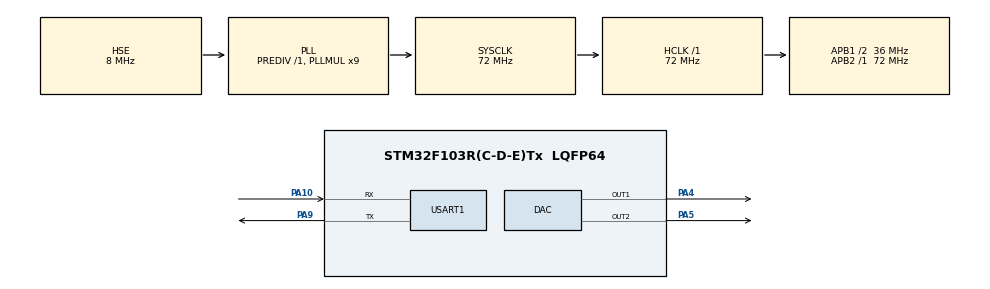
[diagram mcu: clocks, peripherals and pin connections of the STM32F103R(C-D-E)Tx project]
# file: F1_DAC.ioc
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DAC.DAC_Trigger=DAC_TRIGGER_T2_TRGO
DAC.DAC_Trigger2=DAC_TRIGGER_T2_TRGO
Dma.DAC_CH1.0.Direction=DMA_MEMORY_TO_PERIPH
Dma.DAC_CH1.0.Instance=DMA2_Channel3
Dma.DAC_CH1.0.MemDataAlignment=DMA_MDATAALIGN_HALFWORD
Dma.DAC_CH1.0.MemInc=DMA_MINC_ENABLE
Dma.DAC_CH1.0.Mode=DMA_CIRCULAR
Dma.DAC_CH1.0.PeriphDataAlignment=DMA_PDATAALIGN_HALFWORD
Dma.DAC_CH1.0.PeriphInc=DMA_PINC_DISABLE
Dma.DAC_CH1.0.Priority=DMA_PRIORITY_LOW
Dma.DAC_CH2.1.Direction=DMA_MEMORY_TO_PERIPH
Dma.DAC_CH2.1.Instance=DMA2_Channel4
Dma.DAC_CH2.1.MemDataAlignment=DMA_MDATAALIGN_HALFWORD
Dma.DAC_CH2.1.MemInc=DMA_MINC_ENABLE
Dma.DAC_CH2.1.Mode=DMA_CIRCULAR
Dma.DAC_CH2.1.PeriphDataAlignment=DMA_PDATAALIGN_HALFWORD
Dma.DAC_CH2.1.PeriphInc=DMA_PINC_DISABLE
Dma.DAC_CH2.1.Priority=DMA_PRIORITY_LOW
Dma.Request0=DAC_CH1
Dma.Request1=DAC_CH2
Mcu.Family=STM32F1
Mcu.Name=STM32F103R(C-D-E)Tx
Mcu.Package=LQFP64
NVIC.DMA2_Channel3_IRQn=true\:0\:0\:false\:false\:true\:false\:true
NVIC.DMA2_Channel4_5_IRQn=true\:0\:0\:false\:false\:true\:false\:true
NVIC.PriorityGroup=NVIC_PRIORITYGROUP_4
NVIC.TIM3_IRQn=true\:0\:0\:false\:false\:true\:false\:true
NVIC.TimeBase=TIM3_IRQn
NVIC.TimeBaseIP=TIM3
PA10.Mode=Asynchronous
PA10.Signal=USART1_RX
PA13.Mode=Serial_Wire
PA13.Signal=SYS_JTMS-SWDIO
PA14.Mode=Serial_Wire
PA14.Signal=SYS_JTCK-SWCLK
PA4.Signal=COMP_DAC1_group
PA5.Signal=COMP_DAC2_group
PA9.Mode=Asynchronous
PA9.Signal=USART1_TX
PC14-OSC32_IN.Mode=LSE-External-Oscillator
PC14-OSC32_IN.Signal=RCC_OSC32_IN
PC15-OSC32_OUT.Mode=LSE-External-Oscillator
PC15-OSC32_OUT.Signal=RCC_OSC32_OUT
PD0-OSC_IN.Mode=HSE-External-Oscillator
PD0-OSC_IN.Signal=RCC_OSC_IN
PD1-OSC_OUT.Mode=HSE-External-Oscillator
PD1-OSC_OUT.Signal=RCC_OSC_OUT
ProjectManager.HeapSize=0x200
ProjectManager.StackSize=0x400
ProjectManager.TargetToolchain=STM32CubeIDE
RCC.AHBFreq_Value=72000000
RCC.APB1CLKDivider=RCC_HCLK_DIV2
RCC.APB1Freq_Value=36000000
RCC.APB1TimFreq_Value=72000000
RCC.APB2Freq_Value=72000000
RCC.APB2TimFreq_Value=72000000
RCC.EnbaleCSS=true
RCC.HCLKFreq_Value=72000000
RCC.PLLMUL=RCC_PLL_MUL9
RCC.PLLSourceVirtual=RCC_PLLSOURCE_HSE
RCC.SYSCLKFreq_VALUE=72000000
RCC.SYSCLKSource=RCC_SYSCLKSOURCE_PLLCLK
RCC.USBFreq_Value=72000000
SH.COMP_DAC1_group.0=DAC_OUT1,DAC_OUT1
SH.COMP_DAC2_group.0=DAC_OUT2,DAC_OUT2
TIM2.Period=99
TIM2.TIM_MasterOutputTrigger=TIM_TRGO_UPDATE
USART1.VirtualMode=VM_ASYNC
VP_SYS_VS_tim3.Mode=TIM3
VP_TIM2_VS_ClockSourceINT.Mode=Internal
board=custom

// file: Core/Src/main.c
/* USER CODE BEGIN Header */
/**
 ******************************************************************************
 * @file           : main.c
 * @brief          : Main program body
 ******************************************************************************
 * @attention
 *
 * <h2><center>&copy; Copyright (c) 2020 STMicroelectronics.
 * All rights reserved.</center></h2>
 *
 * This software component is licensed by ST under BSD 3-Clause license,
 * the "License"; You may not use this file except in compliance with the
 * License. You may obtain a copy of the License at:
 *                        opensource.org/licenses/BSD-3-Clause
 *
 ******************************************************************************
 */
/* USER CODE END Header */
#include "main.h"

/* USER CODE BEGIN Includes */
#include "MFSK.h"
/* USER CODE END Includes */

TIM_HandleTypeDef htim2;

UART_HandleTypeDef huart1;

void SystemClock_Config(void);
static void MX_GPIO_Init(void);
static void MX_DMA_Init(void);
static void MX_DAC_Init(void);
static void MX_TIM2_Init(void);
static void MX_USART1_UART_Init(void);

int main(void)
{

  /* MCU Configuration--------------------------------------------------------*/

  /* Reset of all peripherals, Initializes the Flash interface and the Systick. */
  HAL_Init();

  /* Configure the system clock */
  SystemClock_Config();

  /* Initialize all configured peripherals */
  MX_GPIO_Init();
  MX_DMA_Init();
  MX_DAC_Init();
  MX_TIM2_Init();
  MX_USART1_UART_Init();
  /* USER CODE BEGIN 2 */
  HAL_TIM_Base_Start_IT (&htim2);
//  TIM2->ARR = 124;
  /* USER CODE END 2 */
//  TIM2->ARR = 99;
  /* Infinite loop */
  /* USER CODE BEGIN WHILE */
  while (1)
    {
      send_msg("SASASASASA",10);
      HAL_TIM_Base_Stop_IT (&htim2);
      while(1){};
//      HAL_Delay(100);
//      TIM2->ARR = 59;
//      HAL_Delay(10);
//      TIM2->ARR = 199;
//      HAL_Delay(10);
//      TIM2->ARR = 299;
//
//      HAL_Delay(1);
//      TIM2->ARR = 399;
//      HAL_Delay(1);
    /* USER CODE END WHILE */

    }
}

void SystemClock_Config(void)
{
  RCC_OscInitTypeDef RCC_OscInitStruct = {0};
  RCC_ClkInitTypeDef RCC_ClkInitStruct = {0};

  /** Initializes the RCC Oscillators according to the specified parameters
  * in the RCC_OscInitTypeDef structure.
  */
  RCC_OscInitStruct.OscillatorType = RCC_OSCILLATORTYPE_HSE;
  RCC_OscInitStruct.HSEState = RCC_HSE_ON;
  RCC_OscInitStruct.HSEPredivValue = RCC_HSE_PREDIV_DIV1;
  RCC_OscInitStruct.HSIState = RCC_HSI_ON;
  RCC_OscInitStruct.PLL.PLLState = RCC_PLL_ON;
  RCC_OscInitStruct.PLL.PLLSource = RCC_PLLSOURCE_HSE;
  RCC_OscInitStruct.PLL.PLLMUL = RCC_PLL_MUL9;
  if (HAL_RCC_OscConfig(&RCC_OscInitStruct) != HAL_OK)
  {
    Error_Handler();
  }
  /** Initializes the CPU, AHB and APB buses clocks
  */
  RCC_ClkInitStruct.ClockType = RCC_CLOCKTYPE_HCLK|RCC_CLOCKTYPE_SYSCLK
                              |RCC_CLOCKTYPE_PCLK1|RCC_CLOCKTYPE_PCLK2;
  RCC_ClkInitStruct.SYSCLKSource = RCC_SYSCLKSOURCE_PLLCLK;
  RCC_ClkInitStruct.AHBCLKDivider = RCC_SYSCLK_DIV1;
  RCC_ClkInitStruct.APB1CLKDivider = RCC_HCLK_DIV2;
  RCC_ClkInitStruct.APB2CLKDivider = RCC_HCLK_DIV1;

  if (HAL_RCC_ClockConfig(&RCC_ClkInitStruct, FLASH_LATENCY_2) != HAL_OK)
  {
    Error_Handler();
  }
  /** Enables the Clock Security System
  */
  HAL_RCC_EnableCSS();
}

static void MX_DAC_Init(void)
{

  LL_DAC_InitTypeDef DAC_InitStruct = {0};

  LL_GPIO_InitTypeDef GPIO_InitStruct = {0};

  /* Peripheral clock enable */
  LL_APB1_GRP1_EnableClock(LL_APB1_GRP1_PERIPH_DAC1);

  LL_APB2_GRP1_EnableClock(LL_APB2_GRP1_PERIPH_GPIOA);
  /**DAC GPIO Configuration
  PA4   ------> DAC_OUT1
  PA5   ------> DAC_OUT2
  */
  GPIO_InitStruct.Pin = LL_GPIO_PIN_4|LL_GPIO_PIN_5;
  GPIO_InitStruct.Mode = LL_GPIO_MODE_ANALOG;
  LL_GPIO_Init(GPIOA, &GPIO_InitStruct);

  /* DAC DMA Init */

  /* DAC_CH1 Init */
  LL_DMA_SetDataTransferDirection(DMA2, LL_DMA_CHANNEL_3, LL_DMA_DIRECTION_MEMORY_TO_PERIPH);

  LL_DMA_SetChannelPriorityLevel(DMA2, LL_DMA_CHANNEL_3, LL_DMA_PRIORITY_LOW);

  LL_DMA_SetMode(DMA2, LL_DMA_CHANNEL_3, LL_DMA_MODE_CIRCULAR);

  LL_DMA_SetPeriphIncMode(DMA2, LL_DMA_CHANNEL_3, LL_DMA_PERIPH_NOINCREMENT);

  LL_DMA_SetMemoryIncMode(DMA2, LL_DMA_CHANNEL_3, LL_DMA_MEMORY_INCREMENT);

  LL_DMA_SetPeriphSize(DMA2, LL_DMA_CHANNEL_3, LL_DMA_PDATAALIGN_HALFWORD);

  LL_DMA_SetMemorySize(DMA2, LL_DMA_CHANNEL_3, LL_DMA_MDATAALIGN_HALFWORD);

  /* DAC_CH2 Init */
  LL_DMA_SetDataTransferDirection(DMA2, LL_DMA_CHANNEL_4, LL_DMA_DIRECTION_MEMORY_TO_PERIPH);

  LL_DMA_SetChannelPriorityLevel(DMA2, LL_DMA_CHANNEL_4, LL_DMA_PRIORITY_LOW);

  LL_DMA_SetMode(DMA2, LL_DMA_CHANNEL_4, LL_DMA_MODE_CIRCULAR);

  LL_DMA_SetPeriphIncMode(DMA2, LL_DMA_CHANNEL_4, LL_DMA_PERIPH_NOINCREMENT);

  LL_DMA_SetMemoryIncMode(DMA2, LL_DMA_CHANNEL_4, LL_DMA_MEMORY_INCREMENT);

  LL_DMA_SetPeriphSize(DMA2, LL_DMA_CHANNEL_4, LL_DMA_PDATAALIGN_HALFWORD);

  LL_DMA_SetMemorySize(DMA2, LL_DMA_CHANNEL_4, LL_DMA_MDATAALIGN_HALFWORD);

  /* USER CODE BEGIN DAC_Init 1 */
  LL_DMA_SetPeriphAddress (DMA2, LL_DMA_CHANNEL_3, (uint32_t) &DAC->DHR12R1);
  LL_DMA_SetMemoryAddress (DMA2, LL_DMA_CHANNEL_3, (uint32_t) &gSinWave[0]);
  LL_DMA_SetDataLength (DMA2, LL_DMA_CHANNEL_3, NS);
  LL_DMA_EnableChannel (DMA2, LL_DMA_CHANNEL_3);

  /* USER CODE END DAC_Init 1 */
  /** DAC channel OUT1 config
  */
  DAC_InitStruct.TriggerSource = LL_DAC_TRIG_EXT_TIM2_TRGO;
  DAC_InitStruct.WaveAutoGeneration = LL_DAC_WAVE_AUTO_GENERATION_NONE;
  DAC_InitStruct.OutputBuffer = LL_DAC_OUTPUT_BUFFER_ENABLE;
  LL_DAC_Init(DAC, LL_DAC_CHANNEL_1, &DAC_InitStruct);
  LL_DAC_EnableTrigger(DAC, LL_DAC_CHANNEL_1);
  /** DAC channel OUT2 config
  */
  LL_DAC_Init(DAC, LL_DAC_CHANNEL_2, &DAC_InitStruct);
  LL_DAC_EnableTrigger(DAC, LL_DAC_CHANNEL_2);
  /* USER CODE BEGIN DAC_Init 2 */
  LL_DAC_Enable (DAC, LL_DAC_CHANNEL_1);
  LL_DAC_EnableDMAReq (DAC, LL_DAC_CHANNEL_1);
  /* USER CODE END DAC_Init 2 */

}

static void MX_TIM2_Init(void)
{

  TIM_ClockConfigTypeDef sClockSourceConfig = {0};
  TIM_MasterConfigTypeDef sMasterConfig = {0};

  htim2.Instance = TIM2;
  htim2.Init.Prescaler = 0;
  htim2.Init.CounterMode = TIM_COUNTERMODE_UP;
  htim2.Init.Period = 0;
  htim2.Init.ClockDivision = TIM_CLOCKDIVISION_DIV1;
  htim2.Init.AutoReloadPreload = TIM_AUTORELOAD_PRELOAD_DISABLE;
  if (HAL_TIM_Base_Init(&htim2) != HAL_OK)
  {
    Error_Handler();
  }
  sClockSourceConfig.ClockSource = TIM_CLOCKSOURCE_INTERNAL;
  if (HAL_TIM_ConfigClockSource(&htim2, &sClockSourceConfig) != HAL_OK)
  {
    Error_Handler();
  }
  sMasterConfig.MasterOutputTrigger = TIM_TRGO_UPDATE;
  sMasterConfig.MasterSlaveMode = TIM_MASTERSLAVEMODE_DISABLE;
  if (HAL_TIMEx_MasterConfigSynchronization(&htim2, &sMasterConfig) != HAL_OK)
  {
    Error_Handler();
  }

}

static void MX_USART1_UART_Init(void)
{

  huart1.Instance = USART1;
  huart1.Init.BaudRate = 115200;
  huart1.Init.WordLength = UART_WORDLENGTH_8B;
  huart1.Init.StopBits = UART_STOPBITS_1;
  huart1.Init.Parity = UART_PARITY_NONE;
  huart1.Init.Mode = UART_MODE_TX_RX;
  huart1.Init.HwFlowCtl = UART_HWCONTROL_NONE;
  huart1.Init.OverSampling = UART_OVERSAMPLING_16;
  if (HAL_UART_Init(&huart1) != HAL_OK)
  {
    Error_Handler();
  }

}

static void MX_DMA_Init(void)
{

  /* Init with LL driver */
  /* DMA controller clock enable */
  LL_AHB1_GRP1_EnableClock(LL_AHB1_GRP1_PERIPH_DMA2);

  /* DMA interrupt init */
  /* DMA2_Channel3_IRQn interrupt configuration */
  NVIC_SetPriority(DMA2_Channel3_IRQn, NVIC_EncodePriority(NVIC_GetPriorityGrouping(),0, 0));
  NVIC_EnableIRQ(DMA2_Channel3_IRQn);
  /* DMA2_Channel4_5_IRQn interrupt configuration */
  NVIC_SetPriority(DMA2_Channel4_5_IRQn, NVIC_EncodePriority(NVIC_GetPriorityGrouping(),0, 0));
  NVIC_EnableIRQ(DMA2_Channel4_5_IRQn);

}

static void MX_GPIO_Init(void)
{

  /* GPIO Ports Clock Enable */
  __HAL_RCC_GPIOC_CLK_ENABLE();
  __HAL_RCC_GPIOD_CLK_ENABLE();
  __HAL_RCC_GPIOA_CLK_ENABLE();

}

void HAL_TIM_PeriodElapsedCallback(TIM_HandleTypeDef *htim)
{
  if (htim->Instance == TIM3) {
    HAL_IncTick();
  }
}

void Error_Handler(void)
{
}

/************************ (C) COPYRIGHT STMicroelectronics *****END OF FILE****/
